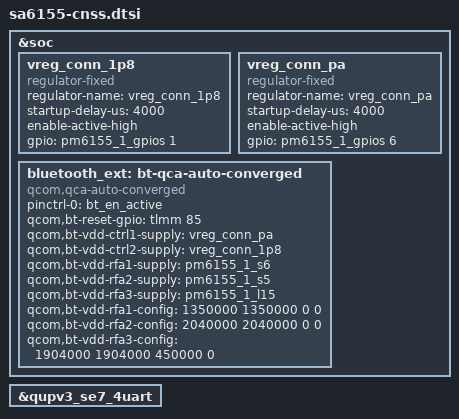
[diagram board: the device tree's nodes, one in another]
&soc {
	/* PWR_CTR2_VDD_1P8 supply */
	vreg_conn_1p8: vreg_conn_1p8 {
		compatible = "regulator-fixed";
		regulator-name = "vreg_conn_1p8";
		startup-delay-us = <4000>;
		enable-active-high;
		gpio = <&pm6155_1_gpios 1 0>;
	};

	/* PWR_CTR1_VDD_PA supply */
	vreg_conn_pa: vreg_conn_pa {
		compatible = "regulator-fixed";
		regulator-name = "vreg_conn_pa";
		startup-delay-us = <4000>;
		enable-active-high;
		gpio = <&pm6155_1_gpios 6 0>;
	};

	bluetooth_ext: bt-qca-auto-converged {
		compatible = "qcom,qca-auto-converged";
		pinctrl-names = "default";
		pinctrl-0 = <&bt_en_active>;
		/* BT_EN */
		qcom,bt-reset-gpio = <&tlmm 85 0>;
		/* PWR_CTR1_VDD_PA */
		qcom,bt-vdd-ctrl1-supply = <&vreg_conn_pa>;
		/* PWR_CTR2_VDD_1P8 */
		qcom,bt-vdd-ctrl2-supply = <&vreg_conn_1p8>;
		qcom,bt-vdd-rfa1-supply = <&pm6155_1_s6>;
		qcom,bt-vdd-rfa2-supply = <&pm6155_1_s5>;
		qcom,bt-vdd-rfa3-supply = <&pm6155_1_l15>;

		/* <vol_min, vol_max, load_curr, is_retention_supp> */
		qcom,bt-vdd-rfa1-config = <1350000 1350000 0 0>;
		qcom,bt-vdd-rfa2-config = <2040000 2040000 0 0>;
		qcom,bt-vdd-rfa3-config = <1904000 1904000 450000 0>;
	};
};

&qupv3_se7_4uart {
	status = "ok";
};
